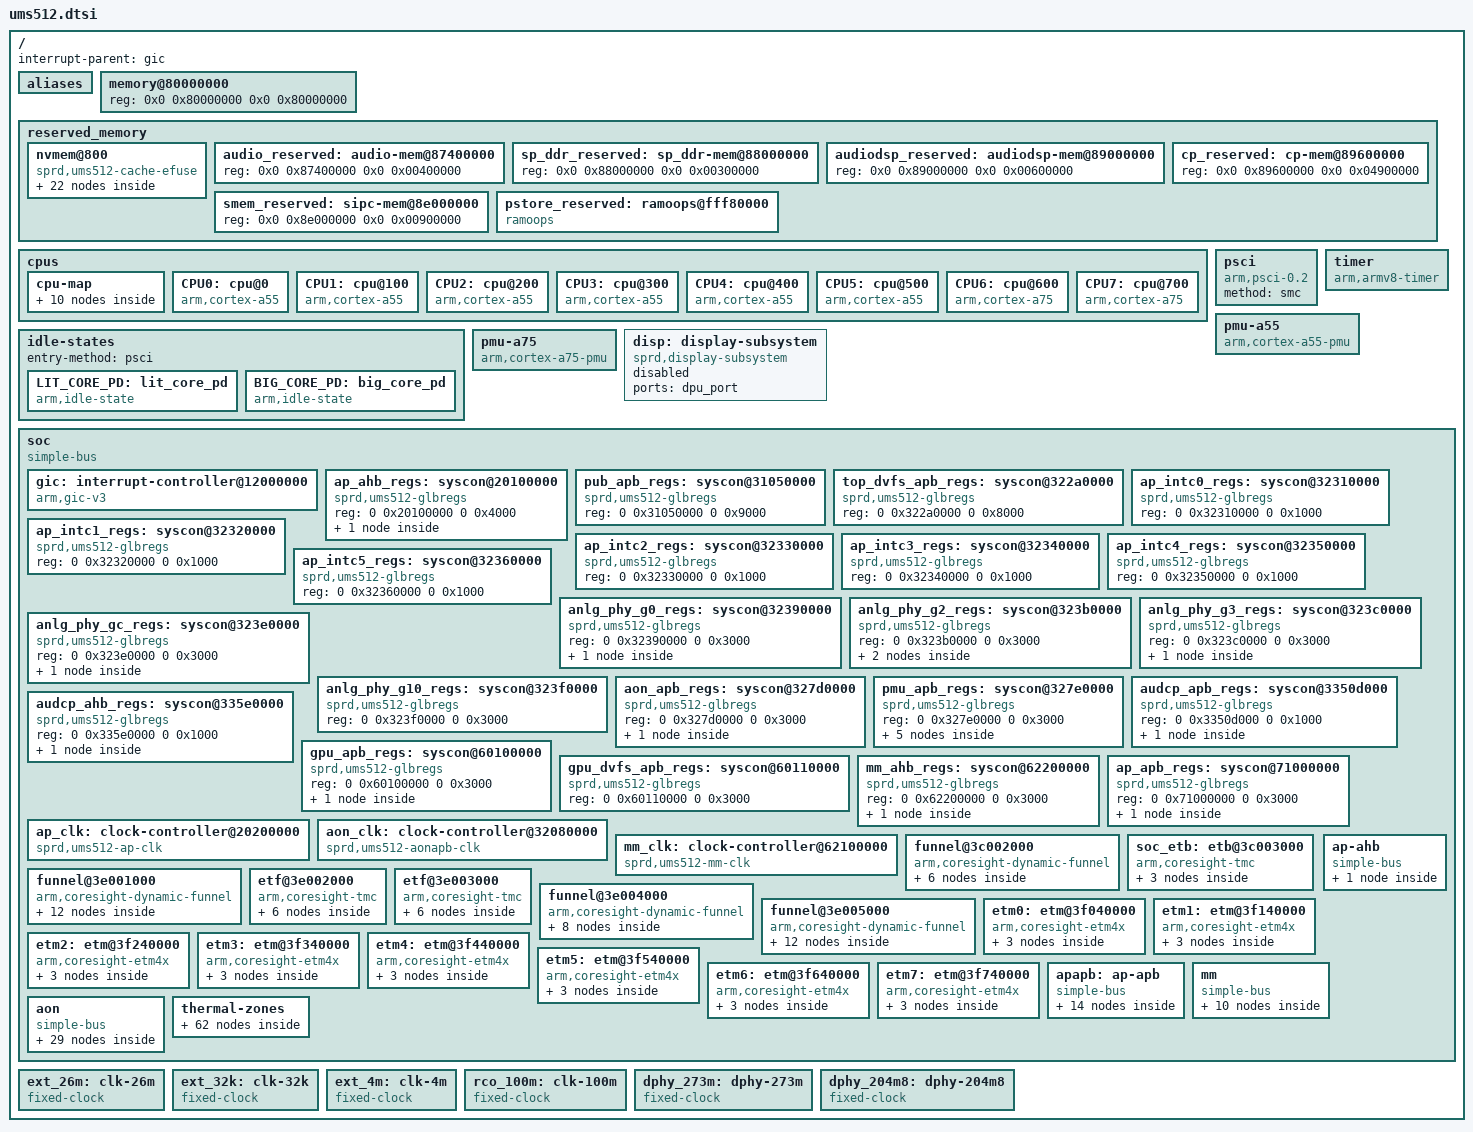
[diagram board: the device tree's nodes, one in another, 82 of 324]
// SPDX-License-Identifier: (GPL-2.0 OR MIT)
/*
 * Unisoc UMS512 SoC DTS file
 *
 * Copyright (C) 2021, Unisoc Inc.
 */

#include <dt-bindings/clock/sprd,ums512-clk.h>
#include <dt-bindings/gpio/gpio.h>
#include <dt-bindings/interrupt-controller/arm-gic.h>
#include <dt-bindings/power/sprd,ums512-power.h>
#include <dt-bindings/reset/sprd,ums512-reset.h>
#include <dt-bindings/thermal/thermal.h>

/ {
	interrupt-parent = <&gic>;
	#address-cells = <2>;
	#size-cells = <2>;

	aliases {
		serial0 = &uart0;
		serial1 = &uart1;
		mmc0 = &sdio0;
		mmc3 = &sdio3;
		i2c0 = &i2c0;
		i2c1 = &i2c1;
		i2c2 = &i2c2;
		i2c3 = &i2c3;
		i2c4 = &i2c4;
		i2c5 = &aon_i2c0;
		spi0 = &spi0;
		spi1 = &spi1;
		spi2 = &spi2;
		spi3 = &spi3;
		spi4 = &adi_bus;
	};

	memory@80000000 {
		device_type = "memory";
		reg = <0x0 0x80000000 0x0 0x80000000>;
	};

	reserved_memory {
		#address-cells = <2>;
		#size-cells = <2>;
		ranges;

		nvmem@800 {
			compatible = "sprd,ums512-cache-efuse", "nvmem-rmem";
			reg = <0 0x800 0 0x3ff>;
			no-map;

			nvmem-layout {
				compatible = "fixed-layout";
				#address-cells = <1>;
				#size-cells = <1>;

				cluster0_dvfs_bin: cluster0-dvfs-bin@17 {
					reg = <0x17 0x1>;
					bits = <0 3>;
				};

				cluster1_dvfs_bin: cluster1-dvfs-bin@1b {
					reg = <0x1b 0x1>;
					bits = <0 3>;
				};

				dvfs_bin_dsu: dvfs-bin@13{
					reg = <0x13 0x1>;
					bits = <0 3>;
				};

				thm0_sign: thm0-sign@38 {
					reg = <0x38 0x1>;
					bits = <0 1>;
				};

				thm0_ratio: thm0-ratio@38 {
					reg = <0x38 0x1>;
					bits = <1 7>;
				};

				thm0_sen0: thm0-sen0@39 {
					reg = <0x39 0x1>;
					bits = <0 8>;
				};

				thm0_sen1: thm0-sen1@41 {
					reg = <0x41 0x1>;
					bits = <0 8>;
				};

				thm0_sen2: thm0-sen2@40 {
					reg = <0x40 0x1>;
					bits = <0 8>;
				};

				thm0_sen3: thm0-sen3@43 {
					reg = <0x43 0x1>;
					bits = <0 8>;
				};

				thm0_sen4: thm0-sen4@42 {
					reg = <0x42 0x1>;
					bits = <0 8>;
				};

				thm1_sign: thm1-sign@3c {
					reg = <0x3c 0x1>;
					bits = <0 1>;
				};

				thm1_ratio: thm1-ratio@3c {
					reg = <0x3c 0x1>;
					bits = <1 7>;
				};

				thm1_sen0: thm1-sen0@3d {
					reg = <0x3d 0x1>;
					bits = <0 8>;
				};

				thm1_sen1: thm1-sen1@2f {
					reg = <0x2f 0x1>;
					bits = <0 8>;
				};

				thm1_sen2: thm1-sen2@2e {
					reg = <0x2e 0x1>;
					bits = <0 8>;
				};

				thm1_sen3: thm1-sen3@29 {
					reg = <0x29 0x1>;
					bits = <0 8>;
				};

				thm1_sen4: thm1-sen4@28 {
					reg = <0x28 0x1>;
					bits = <0 8>;
				};

				thm1_sen5: thm1-sen4@2b {
					reg = <0x2b 0x1>;
					bits = <0 8>;
				};

				thm2_sign: thm2-sign@3e {
					reg = <0x3e 0x1>;
					bits = <0 1>;
				};

				thm2_ratio: thm2-ratio@3e {
					reg = <0x3e 0x1>;
					bits = <1 7>;
				};

				thm2_sen0: thm2-sen0@3f {
					reg = <0x3f 0x1>;
					bits = <0 8>;
				};
			};
		};

		audio_reserved: audio-mem@87400000 {
			reg = <0x0 0x87400000 0x0 0x00400000>;
		};

		sp_ddr_reserved: sp_ddr-mem@88000000 {
			reg = <0x0 0x88000000 0x0 0x00300000>;
		};

		audiodsp_reserved: audiodsp-mem@89000000 {
			reg = <0x0 0x89000000 0x0 0x00600000>;
		};

		cp_reserved: cp-mem@89600000 {
			reg = <0x0 0x89600000 0x0 0x04900000>;
		};

		smem_reserved: sipc-mem@8e000000 {
			reg = <0x0 0x8e000000 0x0 0x00900000>;
		};

		pstore_reserved: ramoops@fff80000 {
			compatible = "ramoops";
			reg = <0x0 0xfff80000 0x0 0x00040000>;
			record-size = <0x8000>;
			console-size = <0x8000>;
			pmsg-size = <0x8000>;
		};
	};

	cpus {
		#address-cells = <2>;
		#size-cells = <0>;

		cpu-map {
			cluster0 {
				core0 {
					cpu = <&CPU0>;
				};
				core1 {
					cpu = <&CPU1>;
				};
				core2 {
					cpu = <&CPU2>;
				};
				core3 {
					cpu = <&CPU3>;
				};
				core4 {
					cpu = <&CPU4>;
				};
				core5 {
					cpu = <&CPU5>;
				};
			};
			cluster1 {
				core0 {
					cpu = <&CPU6>;
				};
				core1 {
					cpu = <&CPU7>;
				};
			};
		};

		CPU0: cpu@0 {
			device_type = "cpu";
			compatible = "arm,cortex-a55";
			reg = <0x0 0x0>;
			enable-method = "psci";
			cpu-idle-states = <&LIT_CORE_PD>;
			clock-frequency = <1820000000>;
			capacity-dmips-mhz = <544>;
			dynamic-power-coefficient = <102>;
			#cooling-cells = <2>;
		};

		CPU1: cpu@100 {
			device_type = "cpu";
			compatible = "arm,cortex-a55";
			reg = <0x0 0x100>;
			enable-method = "psci";
			cpu-idle-states = <&LIT_CORE_PD>;
			clock-frequency = <1820000000>;
			capacity-dmips-mhz = <544>;
			dynamic-power-coefficient = <102>;
			#cooling-cells = <2>;
		};

		CPU2: cpu@200 {
			device_type = "cpu";
			compatible = "arm,cortex-a55";
			reg = <0x0 0x200>;
			enable-method = "psci";
			cpu-idle-states = <&LIT_CORE_PD>;
			clock-frequency = <1820000000>;
			capacity-dmips-mhz = <544>;
			dynamic-power-coefficient = <102>;
			#cooling-cells = <2>;
		};

		CPU3: cpu@300 {
			device_type = "cpu";
			compatible = "arm,cortex-a55";
			reg = <0x0 0x300>;
			enable-method = "psci";
			cpu-idle-states = <&LIT_CORE_PD>;
			clock-frequency = <1820000000>;
			capacity-dmips-mhz = <544>;
			dynamic-power-coefficient = <102>;
			#cooling-cells = <2>;
		};

		CPU4: cpu@400 {
			device_type = "cpu";
			compatible = "arm,cortex-a55";
			reg = <0x0 0x400>;
			enable-method = "psci";
			cpu-idle-states = <&LIT_CORE_PD>;
			clock-frequency = <1820000000>;
			capacity-dmips-mhz = <544>;
			dynamic-power-coefficient = <102>;
			#cooling-cells = <2>;
		};

		CPU5: cpu@500 {
			device_type = "cpu";
			compatible = "arm,cortex-a55";
			reg = <0x0 0x500>;
			enable-method = "psci";
			cpu-idle-states = <&LIT_CORE_PD>;
			clock-frequency = <1820000000>;
			capacity-dmips-mhz = <544>;
			dynamic-power-coefficient = <102>;
			#cooling-cells = <2>;
		};

		CPU6: cpu@600 {
			device_type = "cpu";
			compatible = "arm,cortex-a75";
			reg = <0x0 0x600>;
			enable-method = "psci";
			cpu-idle-states = <&BIG_CORE_PD>;
			clock-frequency = <1820000000>;
			capacity-dmips-mhz = <1024>;
			dynamic-power-coefficient = <501>;
			#cooling-cells = <2>;
		};

		CPU7: cpu@700 {
			device_type = "cpu";
			compatible = "arm,cortex-a75";
			reg = <0x0 0x700>;
			enable-method = "psci";
			cpu-idle-states = <&BIG_CORE_PD>;
			clock-frequency = <1820000000>;
			capacity-dmips-mhz = <1024>;
			dynamic-power-coefficient = <501>;
			#cooling-cells = <2>;
		};
	};

	idle-states {
		entry-method = "psci";

		LIT_CORE_PD: lit_core_pd {
			compatible = "arm,idle-state";
			entry-latency-us = <1000>;
			exit-latency-us = <500>;
			min-residency-us = <2500>;
			local-timer-stop;
			arm,psci-suspend-param = <0x00010000>;
		};

		BIG_CORE_PD: big_core_pd {
			compatible = "arm,idle-state";
			entry-latency-us = <4000>;
			exit-latency-us = <4000>;
			min-residency-us = <10000>;
			local-timer-stop;
			arm,psci-suspend-param = <0x00010000>;
		};
	};

	psci {
		compatible = "arm,psci-0.2";
		method = "smc";
	};

	timer {
		compatible = "arm,armv8-timer";
		interrupts = <GIC_PPI 13 IRQ_TYPE_LEVEL_HIGH>, /* Physical Secure PPI */
			     <GIC_PPI 14 IRQ_TYPE_LEVEL_HIGH>, /* Physical Non-Secure PPI */
			     <GIC_PPI 11 IRQ_TYPE_LEVEL_HIGH>, /* Virtual PPI */
			     <GIC_PPI 10 IRQ_TYPE_LEVEL_HIGH>; /* Hipervisor PPI */
		arm,no-tick-in-suspend;
	};

	pmu-a55 {
		compatible = "arm,cortex-a55-pmu";
		interrupts = <GIC_SPI 112 IRQ_TYPE_LEVEL_HIGH>,
			     <GIC_SPI 113 IRQ_TYPE_LEVEL_HIGH>,
			     <GIC_SPI 114 IRQ_TYPE_LEVEL_HIGH>,
			     <GIC_SPI 115 IRQ_TYPE_LEVEL_HIGH>,
			     <GIC_SPI 116 IRQ_TYPE_LEVEL_HIGH>,
			     <GIC_SPI 117 IRQ_TYPE_LEVEL_HIGH>;
		interrupt-affinity = <&CPU0>, <&CPU1>, <&CPU2>, <&CPU3>, <&CPU4>, <&CPU5>;
	};

	pmu-a75 {
		compatible = "arm,cortex-a75-pmu";
		interrupts = <GIC_SPI 118 IRQ_TYPE_LEVEL_HIGH>,
			     <GIC_SPI 119 IRQ_TYPE_LEVEL_HIGH>;
		interrupt-affinity = <&CPU6>, <&CPU7>;
	};

	disp: display-subsystem {
		compatible = "sprd,display-subsystem";
		ports = <&dpu_port>;

		status = "disabled";
	};

	soc: soc {
		compatible = "simple-bus";
		#address-cells = <2>;
		#size-cells = <2>;
		ranges;

		gic: interrupt-controller@12000000 {
			compatible = "arm,gic-v3";
			reg = <0x0 0x12000000 0 0x20000>,	/* GICD */
			      <0x0 0x12040000 0 0x100000>;	/* GICR */
			#interrupt-cells = <3>;
			#address-cells = <2>;
			#size-cells = <2>;
			ranges;
			redistributor-stride = <0x0 0x20000>;	/* 128KB stride */
			#redistributor-regions = <1>;
			interrupt-controller;
			interrupts = <GIC_PPI 9 IRQ_TYPE_LEVEL_HIGH>;
		};

		ap_ahb_regs: syscon@20100000 {
			compatible = "sprd,ums512-glbregs", "syscon",
				     "simple-mfd";
			reg = <0 0x20100000 0 0x4000>;
			#address-cells = <1>;
			#size-cells = <1>;
			ranges = <0 0 0x20100000 0x4000>;

			apahb_gate: clock-controller@0 {
				compatible = "sprd,ums512-apahb-gate";
				reg = <0x0 0x3000>;
				clocks = <&ext_26m>;
				clock-names = "ext-26m";
				#clock-cells = <1>;
				#reset-cells = <1>;
			};
		};

		pub_apb_regs: syscon@31050000 {
			compatible = "sprd,ums512-glbregs", "syscon",
				     "simple-mfd";
			reg = <0 0x31050000 0 0x9000>;
		};

		top_dvfs_apb_regs: syscon@322a0000 {
			compatible = "sprd,ums512-glbregs", "syscon",
				     "simple-mfd";
			reg = <0 0x322a0000 0 0x8000>;
		};

		ap_intc0_regs: syscon@32310000 {
			compatible = "sprd,ums512-glbregs", "syscon",
				     "simple-mfd";
			reg = <0 0x32310000 0 0x1000>;
		};

		ap_intc1_regs: syscon@32320000 {
			compatible = "sprd,ums512-glbregs", "syscon",
				     "simple-mfd";
			reg = <0 0x32320000 0 0x1000>;
		};

		ap_intc2_regs: syscon@32330000 {
			compatible = "sprd,ums512-glbregs", "syscon",
				     "simple-mfd";
			reg = <0 0x32330000 0 0x1000>;
		};

		ap_intc3_regs: syscon@32340000 {
			compatible = "sprd,ums512-glbregs", "syscon",
				     "simple-mfd";
			reg = <0 0x32340000 0 0x1000>;
		};

		ap_intc4_regs: syscon@32350000 {
			compatible = "sprd,ums512-glbregs", "syscon",
				     "simple-mfd";
			reg = <0 0x32350000 0 0x1000>;
		};

		ap_intc5_regs: syscon@32360000 {
			compatible = "sprd,ums512-glbregs", "syscon",
				     "simple-mfd";
			reg = <0 0x32360000 0 0x1000>;
		};

		anlg_phy_g0_regs: syscon@32390000 {
			compatible = "sprd,ums512-glbregs", "syscon",
				     "simple-mfd";
			reg = <0 0x32390000 0 0x3000>;
			#address-cells = <1>;
			#size-cells = <1>;
			ranges = <0 0 0x32390000 0x3000>;

			dpll0: clock-controller@0 {
				compatible = "sprd,ums512-g0-pll";
				reg = <0x0 0x100>;
				#clock-cells = <1>;
			};
		};

		anlg_phy_g2_regs: syscon@323b0000 {
			compatible = "sprd,ums512-glbregs", "syscon",
				     "simple-mfd";
			reg = <0 0x323b0000 0 0x3000>;
			#address-cells = <1>;
			#size-cells = <1>;
			ranges = <0 0 0x323b0000 0x3000>;

			mpll1: clock-controller@0 {
				compatible = "sprd,ums512-g2-pll";
				reg = <0x0 0x100>;
				#clock-cells = <1>;
			};

			hsphy: phy@100 {
				compatible = "sprd,ums512-hsphy";
				reg = <0x100 0x2000>;
				sprd,syscon-aon-apb = <&aon_apb_regs>;
				#phy-cells = <0>;

				status = "disabled";
			};
		};

		anlg_phy_g3_regs: syscon@323c0000 {
			compatible = "sprd,ums512-glbregs", "syscon",
				     "simple-mfd";
			reg = <0 0x323c0000 0 0x3000>;
			#address-cells = <1>;
			#size-cells = <1>;
			ranges = <0 0 0x323c0000 0x3000>;

			pll1: clock-controller@0 {
				compatible = "sprd,ums512-g3-pll";
				reg = <0x0 0x3000>;
				clocks = <&ext_26m>;
				clock-names = "ext-26m";
				#clock-cells = <1>;
			};
		};

		anlg_phy_gc_regs: syscon@323e0000 {
			compatible = "sprd,ums512-glbregs", "syscon",
				     "simple-mfd";
			reg = <0 0x323e0000 0 0x3000>;
			#address-cells = <1>;
			#size-cells = <1>;
			ranges = <0 0 0x323e0000 0x3000>;

			pll2: clock-controller@0 {
				compatible = "sprd,ums512-gc-pll";
				reg = <0x0 0x100>;
				clocks = <&ext_26m>;
				clock-names = "ext-26m";
				#clock-cells = <1>;
			};
		};

		anlg_phy_g10_regs: syscon@323f0000 {
			compatible = "sprd,ums512-glbregs", "syscon",
				     "simple-mfd";
			reg = <0 0x323f0000 0 0x3000>;
		};

		aon_apb_regs: syscon@327d0000 {
			compatible = "sprd,ums512-glbregs", "syscon",
				     "simple-mfd";
			reg = <0 0x327d0000 0 0x3000>;
			#address-cells = <1>;
			#size-cells = <1>;
			ranges = <0 0 0x327d0000 0x3000>;

			aonapb_gate: clock-controller@0 {
				compatible = "sprd,ums512-aon-gate";
				reg = <0x0 0x3000>;
				clocks = <&ext_26m>;
				clock-names = "ext-26m";
				#clock-cells = <1>;
				#reset-cells = <1>;
			};
		};

		pmu_apb_regs: syscon@327e0000 {
			compatible = "sprd,ums512-glbregs", "syscon",
				     "simple-mfd";
			reg = <0 0x327e0000 0 0x3000>;
			#address-cells = <1>;
			#size-cells = <1>;
			ranges = <0 0 0x327e0000 0x3000>;

			pmu_gate: clock-controller@0 {
				compatible = "sprd,ums512-pmu-gate";
				reg = <0x0 0x3000>;
				clocks = <&ext_26m>;
				clock-names = "ext-26m";
				#clock-cells = <1>;
                                #reset-cells = <1>;
			};

			pmu: power-controller {
				compatible = "sprd,ums512-power-controller";
				#address-cells = <1>;
				#size-cells = <0>;
				#power-domain-cells = <1>;

				power-domain@UMS512_POWER_DOMAIN_GPU_TOP {
					reg = <UMS512_POWER_DOMAIN_GPU_TOP>;
					clocks = <&aonapb_gate CLK_GPU_EB>;
					#power-domain-cells = <0>;
				};

				power-domain@UMS512_POWER_DOMAIN_MM {
					reg = <UMS512_POWER_DOMAIN_MM>;
					clocks = <&aonapb_gate CLK_MM_EB>;
					#power-domain-cells = <0>;
				};

				power-domain@UMS512_POWER_DOMAIN_PUBCP {
					reg = <UMS512_POWER_DOMAIN_PUBCP>;
					#power-domain-cells = <0>;
				};
			};
		};

		audcp_apb_regs: syscon@3350d000 {
			compatible = "sprd,ums512-glbregs", "syscon",
				     "simple-mfd";
			reg = <0 0x3350d000 0 0x1000>;
			#address-cells = <1>;
			#size-cells = <1>;
			ranges = <0 0 0x3350d000 0x1000>;

			audcpapb_gate: clock-controller@0 {
				compatible = "sprd,ums512-audcpapb-gate";
				reg = <0x0 0x300>;
				#clock-cells = <1>;
				#reset-cells = <1>;
			};
		};

		audcp_ahb_regs: syscon@335e0000 {
			compatible = "sprd,ums512-glbregs", "syscon",
				     "simple-mfd";
			reg = <0 0x335e0000 0 0x1000>;
			#address-cells = <1>;
			#size-cells = <1>;
			ranges = <0 0 0x335e0000 0x1000>;

			audcpahb_gate: clock-controller@0 {
				compatible = "sprd,ums512-audcpahb-gate";
				reg = <0x0 0x300>;
				#clock-cells = <1>;
				#reset-cells = <1>;
			};
		};

		gpu_apb_regs: syscon@60100000 {
			compatible = "sprd,ums512-glbregs", "syscon",
				     "simple-mfd";
			reg = <0 0x60100000 0 0x3000>;
			#address-cells = <1>;
			#size-cells = <1>;
			ranges = <0 0 0x60100000 0x3000>;

			gpu_clk: clock-controller@0 {
				compatible = "sprd,ums512-gpu-clk";
				clocks = <&ext_26m>;
				clock-names = "ext-26m";
				reg = <0x0 0x100>;
				#clock-cells = <1>;
				#reset-cells = <1>;
			};
		};

		gpu_dvfs_apb_regs: syscon@60110000 {
			compatible = "sprd,ums512-glbregs", "syscon",
				     "simple-mfd";
			reg = <0 0x60110000 0 0x3000>;
		};

		mm_ahb_regs: syscon@62200000 {
			compatible = "sprd,ums512-glbregs", "syscon",
				     "simple-mfd";
			reg = <0 0x62200000 0 0x3000>;
			#address-cells = <1>;
			#size-cells = <1>;
			ranges = <0 0 0x62200000 0x3000>;

			mm_gate: clock-controller@0 {
				compatible = "sprd,ums512-mm-gate-clk";
				reg = <0x0 0x3000>;
				power-domains = <&pmu UMS512_POWER_DOMAIN_MM>;
				#clock-cells = <1>;
				#reset-cells = <1>;
			};
		};

		ap_apb_regs: syscon@71000000 {
			compatible = "sprd,ums512-glbregs", "syscon",
				     "simple-mfd";
			reg = <0 0x71000000 0 0x3000>;
			#address-cells = <1>;
			#size-cells = <1>;
			ranges = <0 0 0x71000000 0x3000>;

			apapb_gate: clock-controller@0 {
				compatible = "sprd,ums512-apapb-gate";
				reg = <0x0 0x3000>;
				#clock-cells = <1>;
				#reset-cells = <1>;
			};
		};

		ap_clk: clock-controller@20200000 {
			compatible = "sprd,ums512-ap-clk";
			reg = <0 0x20200000 0 0x1000>;
			clocks = <&ext_26m>;
			clock-names = "ext-26m";
			#clock-cells = <1>;
		};

		aon_clk: clock-controller@32080000 {
			compatible = "sprd,ums512-aonapb-clk";
			reg = <0 0x32080000 0 0x1000>;
			clocks = <&ext_26m>, <&ext_32k>,
				 <&ext_4m>, <&rco_100m>;
			clock-names = "ext-26m", "ext-32k",
				      "ext-4m", "rco-100m";
			#clock-cells = <1>;
		};

		mm_clk: clock-controller@62100000 {
			compatible = "sprd,ums512-mm-clk";
			reg = <0 0x62100000 0 0x1000>;
			power-domains = <&pmu UMS512_POWER_DOMAIN_MM>;
			clocks = <&ext_26m>, <&mm_gate CLK_MM_CKG_EB>;
			clock-names = "ext-26m", "enable";
			#clock-cells = <1>;
		};

		/* SoC Funnel */
		funnel@3c002000 {
			compatible = "arm,coresight-dynamic-funnel", "arm,primecell";
			reg = <0 0x3c002000 0 0x1000>;
			clocks = <&ext_26m>;
			clock-names = "apb_pclk";

			out-ports {
				port {
					funnel_soc_out_port: endpoint {
						remote-endpoint = <&etb_in>;
					};
				};
			};

			in-ports {
				#address-cells = <1>;
				#size-cells = <0>;

				port@1 {
					reg = <1>;
					funnel_soc_in_port: endpoint {
						remote-endpoint =
						<&funnel_corinth_out_port>;
					};
				};
			};
		};

		/* SoC ETF */
		soc_etb: etb@3c003000 {
			compatible = "arm,coresight-tmc", "arm,primecell";
			reg = <0 0x3c003000 0 0x1000>;
			clocks = <&ext_26m>;
			clock-names = "apb_pclk";

			in-ports {
				port {
					etb_in: endpoint {
						remote-endpoint =
						<&funnel_soc_out_port>;
					};
				};
			};
		};

		/* AP-CPU Funnel for core3/4/5/7 */
		funnel@3e001000 {
			compatible = "arm,coresight-dynamic-funnel", "arm,primecell";
			reg = <0 0x3e001000 0 0x1000>;
			clocks = <&ext_26m>;
			clock-names = "apb_pclk";

			out-ports {
				port {
					funnel_corinth_lit_out_port: endpoint {
						remote-endpoint =
						<&corinth_etf_lit_in>;
					};
				};
			};

			in-ports {
				#address-cells = <1>;
				#size-cells = <0>;

				port@0 {
					reg = <0>;
					funnel_core_in_port3: endpoint {
						remote-endpoint = <&etm3_out>;
					};
				};

				port@1 {
					reg = <1>;
					funnel_core_in_port4: endpoint {
						remote-endpoint = <&etm4_out>;
					};
				};

				port@2 {
					reg = <2>;
					funnel_core_in_port5: endpoint {
						remote-endpoint = <&etm5_out>;
					};
				};

				port@3 {
					reg = <3>;
					funnel_core_in_port7: endpoint {
						remote-endpoint = <&etm7_out>;
					};
				};
			};
		};

		/* AP-CPU ETF for little cores */
		etf@3e002000 {
			compatible = "arm,coresight-tmc", "arm,primecell";
			reg = <0 0x3e002000 0 0x1000>;
			clocks = <&ext_26m>;
			clock-names = "apb_pclk";

			out-ports {
				port {
					corinth_etf_lit_out: endpoint {
						remote-endpoint =
						<&funnel_corinth_from_lit_in_port>;
					};
				};
			};

			in-ports {
				port {
					corinth_etf_lit_in: endpoint {
						remote-endpoint =
						<&funnel_corinth_lit_out_port>;
					};
				};
			};
		};

		/* AP-CPU ETF for big cores */
		etf@3e003000 {
			compatible = "arm,coresight-tmc", "arm,primecell";
			reg = <0 0x3e003000 0 0x1000>;
			clocks = <&ext_26m>;
			clock-names = "apb_pclk";

			out-ports {
				port {
					corinth_etf_big_out: endpoint {
						remote-endpoint =
						<&funnel_corinth_from_big_in_port>;
					};
				};
			};

			in-ports {
				port {
					corinth_etf_big_in: endpoint {
						remote-endpoint =
						<&funnel_corinth_big_out_port>;
					};
				};
			};
		};

		/* Funnel to SoC */
		funnel@3e004000 {
			compatible = "arm,coresight-dynamic-funnel", "arm,primecell";
			reg = <0 0x3e004000 0 0x1000>;
			clocks = <&ext_26m>;
			clock-names = "apb_pclk";

			out-ports {
				port {
					funnel_corinth_out_port: endpoint {
						remote-endpoint =
						<&funnel_soc_in_port>;
					};
				};
			};

			in-ports {
				#address-cells = <1>;
				#size-cells = <0>;

				port@0 {
					reg = <0>;
					funnel_corinth_from_lit_in_port: endpoint {
						remote-endpoint = <&corinth_etf_lit_out>;
					};
				};

				port@1 {
					reg = <1>;
					funnel_corinth_from_big_in_port: endpoint {
						remote-endpoint = <&corinth_etf_big_out>;
					};
				};
			};
		};

		/* AP-CPU Funnel for core0/1/2/6 */
		funnel@3e005000 {
			compatible = "arm,coresight-dynamic-funnel", "arm,primecell";
			reg = <0 0x3e005000 0 0x1000>;
			clocks = <&ext_26m>;
			clock-names = "apb_pclk";

			out-ports {
				port {
					funnel_corinth_big_out_port: endpoint {
						remote-endpoint = <&corinth_etf_big_in>;
					};
				};
			};

			in-ports {
				#address-cells = <1>;
				#size-cells = <0>;

				port@0 {
					reg = <0>;
					funnel_core_in_port0: endpoint {
						remote-endpoint = <&etm0_out>;
					};
				};

				port@1 {
					reg = <1>;
					funnel_core_in_port1: endpoint {
						remote-endpoint = <&etm1_out>;
					};
				};

				port@2 {
					reg = <2>;
					funnel_core_in_port2: endpoint {
						remote-endpoint = <&etm2_out>;
					};
				};

				port@3 {
					reg = <3>;
					funnel_core_in_port6: endpoint {
						remote-endpoint = <&etm6_out>;
					};
				};
			};
		};

		etm0: etm@3f040000 {
			compatible = "arm,coresight-etm4x", "arm,primecell";
			reg = <0 0x3f040000 0 0x1000>;
			cpu = <&CPU0>;
			clocks = <&ext_26m>;
			clock-names = "apb_pclk";

			out-ports {
				port {
					etm0_out: endpoint {
						remote-endpoint =
						<&funnel_core_in_port0>;
					};
				};
			};
		};

		etm1: etm@3f140000 {
			compatible = "arm,coresight-etm4x", "arm,primecell";
			reg = <0 0x3f140000 0 0x1000>;
			cpu = <&CPU1>;
			clocks = <&ext_26m>;
			clock-names = "apb_pclk";

			out-ports {
				port {
					etm1_out: endpoint {
						remote-endpoint =
						<&funnel_core_in_port1>;
					};
				};
			};
		};

		etm2: etm@3f240000 {
			compatible = "arm,coresight-etm4x", "arm,primecell";
			reg = <0 0x3f240000 0 0x1000>;
			cpu = <&CPU2>;
			clocks = <&ext_26m>;
			clock-names = "apb_pclk";

			out-ports {
				port {
					etm2_out: endpoint {
						remote-endpoint =
						<&funnel_core_in_port2>;
					};
				};
			};
		};

		etm3: etm@3f340000 {
			compatible = "arm,coresight-etm4x", "arm,primecell";
			reg = <0 0x3f340000 0 0x1000>;
			cpu = <&CPU3>;
			clocks = <&ext_26m>;
			clock-names = "apb_pclk";

			out-ports {
				port {
					etm3_out: endpoint {
						remote-endpoint =
						<&funnel_core_in_port3>;
					};
				};
			};
		};

		etm4: etm@3f440000 {
			compatible = "arm,coresight-etm4x", "arm,primecell";
			reg = <0 0x3f440000 0 0x1000>;
			cpu = <&CPU4>;
			clocks = <&ext_26m>;
			clock-names = "apb_pclk";

			out-ports {
				port {
					etm4_out: endpoint {
						remote-endpoint =
						<&funnel_core_in_port4>;
					};
				};
			};
		};

		etm5: etm@3f540000 {
			compatible = "arm,coresight-etm4x", "arm,primecell";
			reg = <0 0x3f540000 0 0x1000>;
			cpu = <&CPU5>;
			clocks = <&ext_26m>;
			clock-names = "apb_pclk";

			out-ports {
				port {
					etm5_out: endpoint {
						remote-endpoint =
						<&funnel_core_in_port5>;
					};
				};
			};
		};

		etm6: etm@3f640000 {
			compatible = "arm,coresight-etm4x", "arm,primecell";
			reg = <0 0x3f640000 0 0x1000>;
			cpu = <&CPU6>;
			clocks = <&ext_26m>;
			clock-names = "apb_pclk";

			out-ports {
				port {
					etm6_out: endpoint {
						remote-endpoint =
						<&funnel_core_in_port6>;
					};
				};
			};
		};

		etm7: etm@3f740000 {
			compatible = "arm,coresight-etm4x", "arm,primecell";
			reg = <0 0x3f740000 0 0x1000>;
			cpu = <&CPU7>;
			clocks = <&ext_26m>;
			clock-names = "apb_pclk";

			out-ports {
				port {
					etm7_out: endpoint {
						remote-endpoint =
						<&funnel_core_in_port7>;
					};
				};
			};
		};

		apapb: ap-apb {
			compatible = "simple-bus";
			#address-cells = <2>;
			#size-cells = <2>;
			ranges;

			uart0: serial@0 {
				compatible = "sprd,ums512-uart",
					     "sprd,sc9836-uart";
				reg = <0 0x0 0 0x100>;
				interrupts = <GIC_SPI 2 IRQ_TYPE_LEVEL_HIGH>;
				clocks = <&ext_26m>;
				status = "disabled";
			};

			uart1: serial@100000 {
				compatible = "sprd,ums512-uart",
					     "sprd,sc9836-uart";
				reg = <0 0x100000 0 0x100>;
				interrupts = <GIC_SPI 3 IRQ_TYPE_LEVEL_HIGH>;
				clocks = <&ext_26m>;
				status = "disabled";
			};

			i2c0: i2c@300000 {
				compatible = "sprd,ums512-i2c", "sprd,sc9860-i2c";
				reg = <0 0x300000 0 0x100>;
				interrupts = <GIC_SPI 11 IRQ_TYPE_LEVEL_HIGH>;
				clock-frequency = <400000>;
				#address-cells = <1>;
				#size-cells = <0>;
				clock-names = "enable", "i2c", "source";
				clocks = <&apapb_gate CLK_I2C0_EB>,
				 <&ap_clk CLK_AP_I2C0>,
				 <&ext_26m>;
				status = "disabled";
			};

			i2c1: i2c@400000 {
				compatible = "sprd,ums512-i2c", "sprd,sc9860-i2c";
				reg = <0 0x400000 0 0x100>;
				interrupts = <GIC_SPI 12 IRQ_TYPE_LEVEL_HIGH>;
				clock-frequency = <400000>;
				#address-cells = <1>;
				#size-cells = <0>;
				clock-names = "enable", "i2c", "source";
				clocks = <&apapb_gate CLK_I2C1_EB>,
				 <&ap_clk CLK_AP_I2C1>,
				 <&ext_26m>;
				status = "disabled";
			};

			i2c2: i2c@500000 {
				compatible = "sprd,ums512-i2c", "sprd,sc9860-i2c";
				reg = <0 0x500000 0 0x100>;
				interrupts = <GIC_SPI 13 IRQ_TYPE_LEVEL_HIGH>;
				clock-frequency = <400000>;
				#address-cells = <1>;
				#size-cells = <0>;
				clock-names = "enable", "i2c", "source";
				clocks = <&apapb_gate CLK_I2C2_EB>,
				 <&ap_clk CLK_AP_I2C2>,
				 <&ext_26m>;
				status = "disabled";
			};

			i2c3: i2c@600000 {
				compatible = "sprd,ums512-i2c", "sprd,sc9860-i2c";
				reg = <0 0x600000 0 0x100>;
				interrupts = <GIC_SPI 14 IRQ_TYPE_LEVEL_HIGH>;
				clock-frequency = <400000>;
				#address-cells = <1>;
				#size-cells = <0>;
				clock-names = "enable", "i2c", "source";
				clocks = <&apapb_gate CLK_I2C3_EB>,
				 <&ap_clk CLK_AP_I2C3>,
				 <&ext_26m>;
				status = "disabled";
			};

			i2c4: i2c@700000 {
				compatible = "sprd,ums512-i2c", "sprd,sc9860-i2c";
				reg = <0 0x700000 0 0x100>;
				interrupts = <GIC_SPI 15 IRQ_TYPE_LEVEL_HIGH>;
				clock-frequency = <400000>;
				#address-cells = <1>;
				#size-cells = <0>;
				clock-names = "enable", "i2c", "source";
				clocks = <&apapb_gate CLK_I2C4_EB>,
				 <&ap_clk CLK_AP_I2C4>,
				 <&ext_26m>;
				status = "disabled";
			};

			spi0: spi@800000{
				compatible = "sprd,ums512-spi", "sprd,sc9860-spi";
				reg = <0 0x800000 0 0x1000>;
				interrupts = <GIC_SPI 5 IRQ_TYPE_LEVEL_HIGH>;
				clocks = <&apapb_gate CLK_SPI0_EB>,
                                 <&ap_clk CLK_AP_SPI0>,
                                 <&pll2 CLK_TWPLL_192M>;
 			        clock-names = "spi", "source", "enable";
				#address-cells = <1>;
				#size-cells = <0>;
				status = "disabled";
			};

			spi1: spi@900000{
				compatible = "sprd,ums512-spi", "sprd,sc9860-spi";
				reg = <0 0x900000 0 0x1000>;
				interrupts = <GIC_SPI 6 IRQ_TYPE_LEVEL_HIGH>;
				clocks = <&apapb_gate CLK_SPI1_EB>,
                                 <&ap_clk CLK_AP_SPI1>,
                                 <&pll2 CLK_TWPLL_192M>;
      		                clock-names = "spi", "source", "enable";
				#address-cells = <1>;
				#size-cells = <0>;
				status = "disabled";
			};

			spi2: spi@a00000{
				compatible = "sprd,ums512-spi", "sprd,sc9860-spi";
				reg = <0 0xa00000 0 0x1000>;
				interrupts = <GIC_SPI 7 IRQ_TYPE_LEVEL_HIGH>;
				clocks = <&apapb_gate CLK_SPI2_EB>,
                                 <&ap_clk CLK_AP_SPI2>,
                                 <&pll2 CLK_TWPLL_192M>;
				clock-names = "spi", "source", "enable";
				#address-cells = <1>;
				#size-cells = <0>;
				status = "disabled";
			};

			spi3: spi@b00000{
				compatible = "sprd,ums512-spi", "sprd,sc9860-spi";
				reg = <0 0xb00000 0 0x1000>;
				interrupts = <GIC_SPI 8 IRQ_TYPE_LEVEL_HIGH>;
				clocks = <&apapb_gate CLK_SPI3_EB>,
                                 <&ap_clk CLK_AP_SPI3>,
                                 <&pll2 CLK_TWPLL_192M>;
				clock-names = "spi", "source", "enable";
				#address-cells = <1>;
				#size-cells = <0>;
				status = "disabled";
			};


			sdio0: mmc@71100000 {
				compatible = "sprd,sdhci-r11";
				reg = <0 0x71100000 0 0x1000>;
				interrupts = <GIC_SPI 19 IRQ_TYPE_LEVEL_HIGH>;
				clocks = <&ap_clk CLK_SDIO0_2X>,
					 <&apapb_gate CLK_SDIO0_EB>;
				clock-names = "sdio", "enable";
				assigned-clocks = <&ap_clk CLK_SDIO0_2X>;
				assigned-clock-parents = <&pll1 CLK_RPLL>;
				status = "disabled";
			};

			sdio1: mmc@71200000 {
				compatible = "sprd,sdhci-r11";
				reg = <0 0x71200000 0 0x1000>;
				interrupts = <GIC_SPI 20 IRQ_TYPE_LEVEL_HIGH>;
				clock-names = "sdio", "enable";
				clocks = <&ap_clk CLK_SDIO1_2X>,
					<&apapb_gate CLK_SDIO1_EB>;
				assigned-clocks = <&ap_clk CLK_SDIO1_2X>;
				assigned-clock-parents = <&pll2 CLK_LPLL_409M6>;
				status = "disabled";
			};

			sdio3: mmc@71400000 {
				compatible = "sprd,sdhci-r11";
				reg = <0 0x71400000 0 0x1000>;
				interrupts = <GIC_SPI 10 IRQ_TYPE_LEVEL_HIGH>;
				clocks = <&ap_clk CLK_EMMC_2X>,
					 <&apapb_gate CLK_EMMC_EB>;
				clock-names = "sdio", "enable";
				assigned-clocks = <&ap_clk CLK_EMMC_2X>;
				assigned-clock-parents = <&pll1 CLK_RPLL>;
				status = "disabled";
			};
		};

		ap-ahb {
			compatible = "simple-bus";
			#address-cells = <2>;
			#size-cells = <2>;
			ranges;

			ap_dma: dma-controller@20000000 {
				compatible = "sprd,ums512-dma", "sprd,sc9860-dma";
				reg = <0 0x20000000 0 0x4000>;
				interrupts = <GIC_SPI 24 IRQ_TYPE_LEVEL_HIGH>;
				#dma-cells = <1>;
				#dma-channels = <28>;
				clock-names = "enable";
				clocks = <&apahb_gate CLK_DMA_PUB_EB>;
			};
		};

		mm: mm {
			compatible = "simple-bus";
			#address-cells = <1>;
			#size-cells = <1>;
			ranges;

			dpu: dpu@20300000 {
				compatible = "sprd,ums512-dpu", "sprd,sharkl3-dpu";
				reg = <0x20300000 0x800>;
				interrupts = <GIC_SPI 27 IRQ_TYPE_LEVEL_HIGH>;
				clocks = <&apahb_gate CLK_DISPC_EB>,
					 <&ap_clk CLK_DISPC0_DPI>;
				clock-names = "core", "dpi";
				iommus = <&iommu_disp>;

				status = "disabled";

				dpu_port: port {
					dpu_out: endpoint {
						remote-endpoint = <&dsi_in>;
					};
				};
			};

			iommu_disp: iommu@20300800 {
				compatible = "sprd,ums512-iommu", "sprd,iommu-v1";
				reg = <0x20300800 0x80>;
				sprd,iova-range = <0x90000000 0x10000000>;
				#iommu-cells = <0>;

				status = "disabled";
			};

			dsi: dsi@20400000 {
				compatible = "sprd,ums512-dsi-host", "sprd,ums9230-dsi-host";
				reg = <0x20400000 0x1000>;
				interrupts = <GIC_SPI 30 IRQ_TYPE_LEVEL_HIGH>,
					     <GIC_SPI 31 IRQ_TYPE_LEVEL_HIGH>;
				clocks = <&apahb_gate CLK_DSI_EB>;
				clock-names = "pclk";

				status = "disabled";

				ports {
					#address-cells = <1>;
					#size-cells = <0>;

					port@0 {
						reg = <0>;
						dsi_in: endpoint {
							remote-endpoint = <&dpu_out>;
						};
					};

					port@1 {
						reg = <1>;
						dsi_out: endpoint { };
					};
				};
			};
		};

		aon: aon {
			compatible = "simple-bus";
			#address-cells = <2>;
			#size-cells = <2>;
			ranges;

			eic_debounce: gpio@32000000 {
				compatible = "sprd,ums512-eic-debounce", "sprd,sc9860-eic-debounce";
				reg = <0 0x32020000 0 0x80>,
				      <0 0x32030000 0 0x80>,
				      <0 0x32230000 0 0x80>,
				      <0 0x32270000 0 0x80>;
				gpio-controller;
				#gpio-cells = <2>;
				interrupt-controller;
				#interrupt-cells = <2>;
				interrupts = <GIC_SPI 72 IRQ_TYPE_LEVEL_HIGH>;
			};

			eic_latch: gpio@32000080 {
				compatible = "sprd,ums512-eic-latch", "sprd,sc9860-eic-latch";
				reg = <0 0x32020080 0 0x20>,
				      <0 0x32030080 0 0x20>,
				      <0 0x32230080 0 0x20>,
				      <0 0x32270080 0 0x20>;
				gpio-controller;
				#gpio-cells = <2>;
				interrupt-controller;
				#interrupt-cells = <2>;
				interrupts = <GIC_SPI 72 IRQ_TYPE_LEVEL_HIGH>;
			};

			eic_async: gpio@320000a0 {
				compatible = "sprd,ums512-eic-async", "sprd,sc9860-eic-async";
				reg = <0 0x320200a0 0 0x20>,
				      <0 0x320300a0 0 0x20>,
				      <0 0x322300a0 0 0x20>,
				      <0 0x322700a0 0 0x20>;
				gpio-controller;
				#gpio-cells = <2>;
				interrupt-controller;
				#interrupt-cells = <2>;
				interrupts = <GIC_SPI 72 IRQ_TYPE_LEVEL_HIGH>;
			};

			eic_sync: gpio@320000c0 {
				compatible = "sprd,ums512-eic-sync", "sprd,sc9860-eic-sync";
				reg = <0 0x320200c0 0 0x20>,
				      <0 0x320300c0 0 0x20>,
				      <0 0x322300c0 0 0x20>,
				      <0 0x322700c0 0 0x20>;
				gpio-controller;
				#gpio-cells = <2>;
				interrupt-controller;
				#interrupt-cells = <2>;
				interrupts = <GIC_SPI 72 IRQ_TYPE_LEVEL_HIGH>;
			};

			/*timer@32050000 {
				compatible = "sprd,ums512-timer", "sprd,sc9860-timer";
				reg = <0 0x32050000 0 0x20>;
				interrupts = <GIC_SPI 71 IRQ_TYPE_LEVEL_HIGH>;
				clocks = <&ext_32k>;
			};*/

			timer@32050020 {
				compatible = "sprd,ums512-suspend-timer", "sprd,sc9860-suspend-timer";
				reg = <0 0x32050020 0 0x20>;
				clocks = <&ext_32k>;
			};

			aon_i2c0: i2c@32060000 {
				compatible = "sprd,ums512-hw-i2c";
				reg = <0 0x32060000 0 0x1000>;
				interrupts = <GIC_SPI 68 IRQ_TYPE_LEVEL_HIGH>;
				clocks = <&aonapb_gate CLK_I2C_EB>,
					 <&aon_clk CLK_AON_I2C>,
					 <&ext_26m>;
				clock-names = "source", "enable", "i2c";
				clock-frequency = <400000>;
				#address-cells = <1>;
				#size-cells = <0>;
				status = "disabled";
			};

			ap_gpio: gpio@32070000 {
				compatible = "sprd,ums512-gpio", "sprd,sc9860-gpio";
				reg = <0 0x32070000 0 0x10000>;
				gpio-controller;
				#gpio-cells = <2>;
				interrupt-controller;
				#interrupt-cells = <2>;
				interrupts = <GIC_SPI 61 IRQ_TYPE_LEVEL_HIGH>;
			};

			adi_bus: spi@32100000 {
				compatible = "sprd,ums512-adi";
				reg = <0 0x32100000 0 0x100000>;
				#address-cells = <1>;
				#size-cells = <0>;
				sprd,hw-channels = <2 0x18cc>, <3 0x18cc>, <13 0x1854>, <15 0x1874>,
						   <17 0x1844>,<19 0x1844>, <21 0x1864>, <30 0x1820>,
						   <35 0x19b8>, <39 0x19ac>;
			};

			ap_thm0: thermal@32200000 {
				compatible = "sprd,ums512-thermal";
				reg = <0 0x32200000 0 0x10000>;
				#address-cells = <1>;
				#size-cells = <0>;
				clock-names = "enable";
				clocks = <&aonapb_gate CLK_THM0_EB>;
				#thermal-sensor-cells = <1>;
				nvmem-cells = <&thm0_sign>, <&thm0_ratio>;
				nvmem-cell-names = "thm_sign_cal", "thm_ratio_cal";

				sensor@0 {
					reg = <0>;
					nvmem-cells = <&thm0_sen0>;
					nvmem-cell-names = "sen_delta_cal";
				};

				sensor@1 {
					reg = <1>;
					nvmem-cells = <&thm0_sen1>;
					nvmem-cell-names = "sen_delta_cal";
				};

				sensor@2 {
					reg = <2>;
					nvmem-cells = <&thm0_sen2>;
					nvmem-cell-names = "sen_delta_cal";
				};

				sensor@3 {
					reg = <3>;
					nvmem-cells = <&thm0_sen3>;
					nvmem-cell-names = "sen_delta_cal";
				};

				sensor@4 {
					reg = <4>;
					nvmem-cells = <&thm0_sen4>;
					nvmem-cell-names = "sen_delta_cal";
				};
			};

			ap_thm1: thermal@32210000 {
				compatible = "sprd,ums512-thermal";
				reg = <0 0x32210000 0 0x10000>;
				#address-cells = <1>;
				#size-cells = <0>;
				clock-names = "enable";
				clocks = <&aonapb_gate CLK_THM1_EB>;
				#thermal-sensor-cells = <1>;
				nvmem-cells = <&thm1_sign>, <&thm1_ratio>;
				nvmem-cell-names = "thm_sign_cal", "thm_ratio_cal";

				sensor@0 {
					reg = <0>;
					nvmem-cells = <&thm1_sen0>;
					nvmem-cell-names = "sen_delta_cal";
				};

				sensor@1 {
					reg = <1>;
					nvmem-cells = <&thm1_sen1>;
					nvmem-cell-names = "sen_delta_cal";
				};

				sensor@2 {
					reg = <2>;
					nvmem-cells = <&thm1_sen2>;
					nvmem-cell-names = "sen_delta_cal";
				};

				sensor@3 {
					reg = <3>;
					nvmem-cells = <&thm1_sen3>;
					nvmem-cell-names = "sen_delta_cal";
				};

				sensor@4 {
					reg = <4>;
					nvmem-cells = <&thm1_sen4>;
					nvmem-cell-names = "sen_delta_cal";
				};

				sensor@5 {
					reg = <5>;
					nvmem-cells = <&thm1_sen5>;
					nvmem-cell-names = "sen_delta_cal";
				};
			};

			ap_thm2: thermal@32220000 {
				compatible = "sprd,ums512-thermal";
				reg = <0 0x32220000 0 0x10000>;
				#address-cells = <1>;
				#size-cells = <0>;
				clock-names = "enable";
				clocks = <&aonapb_gate CLK_THM2_EB>;
				#thermal-sensor-cells = <1>;
				nvmem-cells = <&thm2_sign>, <&thm2_ratio>;
				nvmem-cell-names = "thm_sign_cal", "thm_ratio_cal";

				sensor@0 {
					reg = <0>;
					nvmem-cells = <&thm2_sen0>;
					nvmem-cell-names = "sen_delta_cal";
				};
			};

			ap_efuse: efuse@32240000 {
				compatible = "sprd,ums312-efuse", "sprd,ums512-efuse";
				reg = <0 0x32240000 0 0x10000>;
				clock-names = "enable";
				hwlocks = <&hwlock 8>;
				clocks = <&aonapb_gate CLK_EFUSE_EB>;
			};

			pwm: pwm@32260000 {
				compatible = "sprd,ums512-pwm";
				reg = <0 0x32260000 0 0x10000>;
				clocks = <&aon_clk CLK_PWM0>, <&aonapb_gate CLK_PWM0_EB>,
				 <&aon_clk CLK_PWM1>, <&aonapb_gate CLK_PWM1_EB>,
				 <&aon_clk CLK_PWM2>, <&aonapb_gate CLK_PWM2_EB>,
				 <&aon_clk CLK_PWM3>, <&aonapb_gate CLK_PWM3_EB>;
			        clock-names = "pwm0", "enable0",
				      "pwm1", "enable1",
				      "pwm2", "enable2",
				      "pwm3", "enable3";
			        assigned-clocks = <&aon_clk CLK_PWM0>,
					  <&aon_clk CLK_PWM1>,
					  <&aon_clk CLK_PWM2>,
					  <&aon_clk CLK_PWM3>;
			        assigned-clock-parents = <&ext_26m>,
						 <&ext_26m>,
						 <&ext_26m>,
						 <&ext_26m>;
			        #pwm-cells = <2>;
			};

			watchdog@322f0000 {
				compatible = "sprd,ums512-wdt", "sprd,sp9860-wdt";
				reg = <0 0x322f0000 0 0x10000>;
				interrupts = <GIC_SPI 79 IRQ_TYPE_LEVEL_HIGH>;
				timeout-sec = <12>;
				clock-names = "enable", "rtc_enable";
				clocks = <&aonapb_gate CLK_APCPU_WDG_EB>,
				       <&aonapb_gate CLK_AC_WDG_RTC_EB>;
			};

			pinctrl: pinctrl@32450000 {
				compatible = "sprd,ums512-pinctrl";
				reg = <0 0x32450000 0 0x3000>;
			};

			usb: usb@5fff0000 {
				compatible = "sprd,ums512-musb", "sprd,musb";
				reg = <0 0x5fff0000 0 0x2000>;
				interrupts = <GIC_SPI 69 IRQ_TYPE_LEVEL_HIGH>;
				interrupt-names = "mc";
				clocks = <&aonapb_gate CLK_OTG_UTMI_EB>;
				phys = <&hsphy>;

				status = "disabled";
			};

			hwlock: hwspinlock@327f0000 {
				compatible = "sprd,hwspinlock-r3p0";
				reg = <0 0x327f0000 0 0x10000>;
				#hwlock-cells = <1>;
				clocks = <&aonapb_gate CLK_SPLK_EB>;
                                clock-names = "enable";
			};
		};

		thermal-zones {
			cputop0-thermal {
				polling-delay-passive = <100>;

				thermal-sensors = <&ap_thm0 0>;

				trips {
					cputop0_alert0: trip-point0 {
						temperature = <70000>;
						hysteresis = <1000>;
						type = "passive";
					};

					cputop0_critical: cpu-crit {
						temperature = <110000>;
						hysteresis = <2000>;
						type = "critical";
					};
				};

				cooling-maps {
					map0 {
						trip = <&cputop0_alert0>;
						cooling-device = <&CPU0 THERMAL_NO_LIMIT THERMAL_NO_LIMIT>,
								 <&CPU1 THERMAL_NO_LIMIT THERMAL_NO_LIMIT>,
								 <&CPU2 THERMAL_NO_LIMIT THERMAL_NO_LIMIT>,
								 <&CPU3 THERMAL_NO_LIMIT THERMAL_NO_LIMIT>,
								 <&CPU4 THERMAL_NO_LIMIT THERMAL_NO_LIMIT>,
								 <&CPU5 THERMAL_NO_LIMIT THERMAL_NO_LIMIT>;
					};
				};
			};

			ank0-thermal {
				polling-delay-passive = <100>;

				thermal-sensors = <&ap_thm0 3>;

				trips {
					cpu0_alert0: trip-point0 {
						temperature = <70000>;
						hysteresis = <1000>;
						type = "passive";
					};

					cpu0_critical: cpu-crit {
						temperature = <110000>;
						hysteresis = <2000>;
						type = "critical";
					};
				};

				cooling-maps {
					map0 {
						trip = <&cpu0_alert0>;
						cooling-device = <&CPU0 THERMAL_NO_LIMIT THERMAL_NO_LIMIT>;
					};
				};
			};

			ank1-thermal {
				polling-delay-passive = <100>;

				thermal-sensors = <&ap_thm0 4>;

				trips {
					cpu1_alert0: trip-point0 {
						temperature = <70000>;
						hysteresis = <1000>;
						type = "passive";
					};

					cpu1_critical: cpu-crit {
						temperature = <110000>;
						hysteresis = <2000>;
						type = "critical";
					};
				};

				cooling-maps {
					map0 {
						trip = <&cpu1_alert0>;
						cooling-device = <&CPU1 THERMAL_NO_LIMIT THERMAL_NO_LIMIT>;
					};
				};
			};

			ank2-thermal {
				polling-delay-passive = <100>;

				thermal-sensors = <&ap_thm1 1>;

				trips {
					cpu2_alert0: trip-point0 {
						temperature = <70000>;
						hysteresis = <1000>;
						type = "passive";
					};

					cpu2_critical: cpu-crit {
						temperature = <110000>;
						hysteresis = <2000>;
						type = "critical";
					};
				};

				cooling-maps {
					map0 {
						trip = <&cpu2_alert0>;
						cooling-device = <&CPU2 THERMAL_NO_LIMIT THERMAL_NO_LIMIT>;
					};
				};
			};

			prometheus7-thermal {
				polling-delay-passive = <100>;

				thermal-sensors = <&ap_thm0 2>;

				trips {
					cpu7_alert0: trip-point0 {
						temperature = <70000>;
						hysteresis = <1000>;
						type = "passive";
					};

					cpu7_critical: cpu-crit {
						temperature = <110000>;
						hysteresis = <2000>;
						type = "critical";
					};
				};

				cooling-maps {
					map0 {
						trip = <&cpu7_alert0>;
						cooling-device = <&CPU7 THERMAL_NO_LIMIT THERMAL_NO_LIMIT>;
					};
				};
			};

			cputop1-thermal {
				polling-delay-passive = <100>;

				thermal-sensors = <&ap_thm0 1>;

				trips {
					cputop1_alert0: trip-point0 {
						temperature = <70000>;
						hysteresis = <1000>;
						type = "passive";
					};

					cputop1_critical: cpu-crit {
						temperature = <110000>;
						hysteresis = <2000>;
						type = "critical";
					};
				};

				cooling-maps {
					map0 {
						trip = <&cputop1_alert0>;
						cooling-device = <&CPU6 THERMAL_NO_LIMIT THERMAL_NO_LIMIT>,
								 <&CPU7 THERMAL_NO_LIMIT THERMAL_NO_LIMIT>;
					};
				};
			};

			gpu-thermal {
				polling-delay-passive = <100>;

				thermal-sensors = <&ap_thm1 0>;
			};

			gpuank2_thmzone: gpuank2-thmzone {
				polling-delay-passive = <0>;
				polling-delay = <0>;
				thermal-sensors = <&ap_thm2 0>;
			};

			ank3-thermal {
				polling-delay-passive = <100>;

				thermal-sensors = <&ap_thm1 2>;

				trips {
					cpu3_alert0: trip-point0 {
						temperature = <70000>;
						hysteresis = <1000>;
						type = "passive";
					};

					cpu3_critical: cpu-crit {
						temperature = <110000>;
						hysteresis = <2000>;
						type = "critical";
					};
				};

				cooling-maps {
					map0 {
						trip = <&cpu3_alert0>;
						cooling-device = <&CPU3 THERMAL_NO_LIMIT THERMAL_NO_LIMIT>;
					};
				};
			};

			ank4-thermal {
				polling-delay-passive = <100>;

				thermal-sensors = <&ap_thm1 3>;

				trips {
					cpu4_alert0: trip-point0 {
						temperature = <70000>;
						hysteresis = <1000>;
						type = "passive";
					};

					cpu4_critical: cpu-crit {
						temperature = <110000>;
						hysteresis = <2000>;
						type = "critical";
					};
				};

				cooling-maps {
					map0 {
						trip = <&cpu4_alert0>;
						cooling-device = <&CPU4 THERMAL_NO_LIMIT THERMAL_NO_LIMIT>;
					};
				};
			};

			ank5-thermal {
				polling-delay-passive = <100>;

				thermal-sensors = <&ap_thm1 4>;

				trips {
					cpu5_alert0: trip-point0 {
						temperature = <70000>;
						hysteresis = <1000>;
						type = "passive";
					};

					cpu5_critical: cpu-crit {
						temperature = <110000>;
						hysteresis = <2000>;
						type = "critical";
					};
				};

				cooling-maps {
					map0 {
						trip = <&cpu5_alert0>;
						cooling-device = <&CPU5 THERMAL_NO_LIMIT THERMAL_NO_LIMIT>;
					};
				};
			};

			prometheus6-thermal {
				polling-delay-passive = <100>;

				thermal-sensors = <&ap_thm1 5>;

				trips {
					cpu6_alert0: trip-point0 {
						temperature = <70000>;
						hysteresis = <1000>;
						type = "passive";
					};

					cpu6_critical: cpu-crit {
						temperature = <110000>;
						hysteresis = <2000>;
						type = "critical";
					};
				};

				cooling-maps {
					map0 {
						trip = <&cpu6_alert0>;
						cooling-device = <&CPU6 THERMAL_NO_LIMIT THERMAL_NO_LIMIT>;
					};
				};
			};
		};
	};

	ext_26m: clk-26m {
		compatible = "fixed-clock";
		#clock-cells = <0>;
		clock-frequency = <26000000>;
		clock-output-names = "ext-26m";
	};

	ext_32k: clk-32k {
		compatible = "fixed-clock";
		#clock-cells = <0>;
		clock-frequency = <32768>;
		clock-output-names = "ext-32k";
	};

	ext_4m: clk-4m {
		compatible = "fixed-clock";
		#clock-cells = <0>;
		clock-frequency = <4000000>;
		clock-output-names = "ext-4m";
	};

	rco_100m: clk-100m {
		compatible = "fixed-clock";
		#clock-cells = <0>;
		clock-frequency = <100000000>;
		clock-output-names = "rco-100m";
	};

	dphy_273m: dphy-273m {
		compatible = "fixed-clock";
		#clock-cells = <0>;
		clock-frequency = <273000000>;
		clock-output-names = "dphy-273m";
	};

	dphy_204m8: dphy-204m8 {
		compatible = "fixed-clock";
		#clock-cells = <0>;
		clock-frequency = <204800000>;
		clock-output-names = "dphy-204m8";
	};
};
